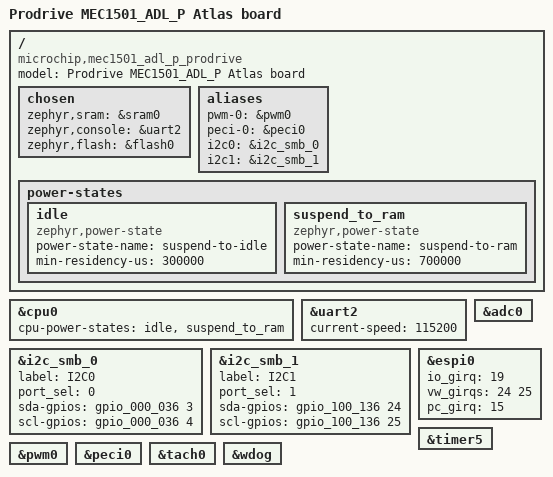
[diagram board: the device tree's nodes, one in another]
/*
 * Copyright (c) 2022, Intel Corporation
 *
 * SPDX-License-Identifier: Apache-2.0
 */

/dts-v1/;

#include <microchip/mec1501hsz.dtsi>

/ {
	model = "Prodrive MEC1501_ADL_P Atlas board";
	compatible = "microchip,mec1501_adl_p_prodrive",
		"microchip,mec1501hsz";

	chosen {
		zephyr,sram = &sram0;
		zephyr,console = &uart2;
		zephyr,flash = &flash0;
	};

	aliases {
		pwm-0 = &pwm0;
		peci-0 = &peci0;

		i2c0 = &i2c_smb_0;
		i2c1 = &i2c_smb_1;
	};

	power-states {
		idle: idle {
			compatible = "zephyr,power-state";
			power-state-name = "suspend-to-idle";
			min-residency-us = <300000>;
		};

		suspend_to_ram: suspend_to_ram {
			compatible = "zephyr,power-state";
			power-state-name = "suspend-to-ram";
			min-residency-us = <700000>;
		};
	};
};

&cpu0 {
	cpu-power-states = <&idle &suspend_to_ram>;
};

&uart2 {
	status = "okay";
	current-speed = <115200>;
};

&adc0 {
	status = "okay";
};

&i2c_smb_0 {
	status = "okay";
	label = "I2C0";
	port_sel = <0>;
	sda-gpios = <&gpio_000_036 3 0>;
	scl-gpios = <&gpio_000_036 4 0>;
};

&i2c_smb_1 {
	status = "okay";
	label = "I2C1";
	port_sel = <1>;
	sda-gpios = <&gpio_100_136 24 0>;
	scl-gpios = <&gpio_100_136 25 0>;
};

&espi0 {
	status = "okay";
	io_girq = <19>;
	vw_girqs = <24 25>;
	pc_girq = <15>;
};

&timer5 {
	status = "okay";
};

&pwm0 {
	status = "okay";
};

&peci0 {
	status = "okay";
};

&tach0 {
	status = "okay";
};

&wdog {
	status = "okay";
};
